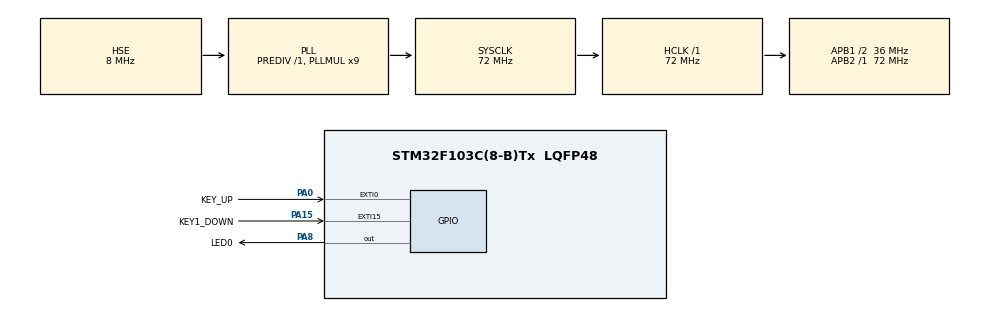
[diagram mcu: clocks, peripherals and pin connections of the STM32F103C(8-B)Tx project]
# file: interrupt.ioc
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Mcu.Family=STM32F1
Mcu.Name=STM32F103C(8-B)Tx
Mcu.Package=LQFP48
NVIC.EXTI0_IRQn=true\:2\:2\:true\:false\:true\:true\:true\:true
NVIC.EXTI15_10_IRQn=true\:2\:2\:true\:false\:true\:true\:true\:true
NVIC.PriorityGroup=NVIC_PRIORITYGROUP_2
PA0-WKUP.GPIO_Label=KEY_UP
PA0-WKUP.GPIO_PuPd=GPIO_PULLDOWN
PA0-WKUP.Signal=GPXTI0
PA13.Mode=Serial_Wire
PA13.Signal=SYS_JTMS-SWDIO
PA14.Mode=Serial_Wire
PA14.Signal=SYS_JTCK-SWCLK
PA15.GPIO_Label=KEY1_DOWN
PA15.GPIO_ModeDefaultEXTI=GPIO_MODE_IT_FALLING
PA15.GPIO_PuPd=GPIO_PULLUP
PA15.Signal=GPXTI15
PA8.GPIO_Label=LED0
PA8.Signal=GPIO_Output
PC14-OSC32_IN.Mode=LSE-External-Oscillator
PC14-OSC32_IN.Signal=RCC_OSC32_IN
PC15-OSC32_OUT.Mode=LSE-External-Oscillator
PC15-OSC32_OUT.Signal=RCC_OSC32_OUT
PD0-OSC_IN.Mode=HSE-External-Oscillator
PD0-OSC_IN.Signal=RCC_OSC_IN
PD1-OSC_OUT.Mode=HSE-External-Oscillator
PD1-OSC_OUT.Signal=RCC_OSC_OUT
ProjectManager.HeapSize=0x200
ProjectManager.StackSize=0x400
ProjectManager.TargetToolchain=Makefile
RCC.AHBFreq_Value=72000000
RCC.APB1CLKDivider=RCC_HCLK_DIV2
RCC.APB1Freq_Value=36000000
RCC.APB1TimFreq_Value=72000000
RCC.APB2Freq_Value=72000000
RCC.APB2TimFreq_Value=72000000
RCC.HCLKFreq_Value=72000000
RCC.PLLMUL=RCC_PLL_MUL9
RCC.PLLSourceVirtual=RCC_PLLSOURCE_HSE
RCC.SYSCLKFreq_VALUE=72000000
RCC.SYSCLKSource=RCC_SYSCLKSOURCE_PLLCLK
RCC.USBFreq_Value=72000000
board=custom

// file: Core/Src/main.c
/* USER CODE BEGIN Header */
/**
  ******************************************************************************
  * @file           : main.c
  * @brief          : Main program body
  ******************************************************************************
  * @attention
  *
  * Copyright (c) 2024 STMicroelectronics.
  * All rights reserved.
  *
  * This software is licensed under terms that can be found in the LICENSE file
  * in the root directory of this software component.
  * If no LICENSE file comes with this software, it is provided AS-IS.
  *
  ******************************************************************************
  */
/* USER CODE END Header */
#include "main.h"

/* USER CODE BEGIN Includes */
#include "delay.h"
#include "oled.h"
/* USER CODE END Includes */

void SystemClock_Config(void);
static void MX_GPIO_Init(void);

int main(void)
{

  /* MCU Configuration--------------------------------------------------------*/

  /* Reset of all peripherals, Initializes the Flash interface and the Systick. */
  HAL_Init();

  /* Configure the system clock */
  SystemClock_Config();

  /* USER CODE BEGIN SysInit */
    delay_init(72);
    OLED_Init();
  /* USER CODE END SysInit */

  /* Initialize all configured peripherals */
  MX_GPIO_Init();

  /* Infinite loop */
  /* USER CODE BEGIN WHILE */
//    OLED_Init();

    counter = 0;
    uint16_t t_counter = counter;
    /*在(16, 0)位置显示字符串"Hello World!"，字体大小为8*16点阵*/
    OLED_ShowString(1, 1, "Counter: ", OLED_8X16);

    OLED_Update();

  while (1)
  {
    /* USER CODE END WHILE */
    if (t_counter != counter) {
        t_counter = counter;
        OLED_ShowNum(65, 1, t_counter, 5, OLED_8X16);
        OLED_Update();
    }

  }
}

void SystemClock_Config(void)
{
  RCC_OscInitTypeDef RCC_OscInitStruct = {0};
  RCC_ClkInitTypeDef RCC_ClkInitStruct = {0};

  /** Initializes the RCC Oscillators according to the specified parameters
  * in the RCC_OscInitTypeDef structure.
  */
  RCC_OscInitStruct.OscillatorType = RCC_OSCILLATORTYPE_HSE;
  RCC_OscInitStruct.HSEState = RCC_HSE_ON;
  RCC_OscInitStruct.HSEPredivValue = RCC_HSE_PREDIV_DIV1;
  RCC_OscInitStruct.HSIState = RCC_HSI_ON;
  RCC_OscInitStruct.PLL.PLLState = RCC_PLL_ON;
  RCC_OscInitStruct.PLL.PLLSource = RCC_PLLSOURCE_HSE;
  RCC_OscInitStruct.PLL.PLLMUL = RCC_PLL_MUL9;
  if (HAL_RCC_OscConfig(&RCC_OscInitStruct) != HAL_OK)
  {
    Error_Handler();
  }

  /** Initializes the CPU, AHB and APB buses clocks
  */
  RCC_ClkInitStruct.ClockType = RCC_CLOCKTYPE_HCLK|RCC_CLOCKTYPE_SYSCLK
                              |RCC_CLOCKTYPE_PCLK1|RCC_CLOCKTYPE_PCLK2;
  RCC_ClkInitStruct.SYSCLKSource = RCC_SYSCLKSOURCE_PLLCLK;
  RCC_ClkInitStruct.AHBCLKDivider = RCC_SYSCLK_DIV1;
  RCC_ClkInitStruct.APB1CLKDivider = RCC_HCLK_DIV2;
  RCC_ClkInitStruct.APB2CLKDivider = RCC_HCLK_DIV1;

  if (HAL_RCC_ClockConfig(&RCC_ClkInitStruct, FLASH_LATENCY_2) != HAL_OK)
  {
    Error_Handler();
  }
}

static void MX_GPIO_Init(void)
{
  GPIO_InitTypeDef GPIO_InitStruct = {0};

  /* GPIO Ports Clock Enable */
  __HAL_RCC_GPIOC_CLK_ENABLE();
  __HAL_RCC_GPIOA_CLK_ENABLE();

  /*Configure GPIO pin Output Level */
  HAL_GPIO_WritePin(LED0_GPIO_Port, LED0_Pin, GPIO_PIN_RESET);

  /*Configure GPIO pin : KEY_UP_Pin */
  GPIO_InitStruct.Pin = KEY_UP_Pin;
  GPIO_InitStruct.Mode = GPIO_MODE_IT_RISING;
  GPIO_InitStruct.Pull = GPIO_PULLDOWN;
  HAL_GPIO_Init(KEY_UP_GPIO_Port, &GPIO_InitStruct);

  /*Configure GPIO pin : LED0_Pin */
  GPIO_InitStruct.Pin = LED0_Pin;
  GPIO_InitStruct.Mode = GPIO_MODE_OUTPUT_PP;
  GPIO_InitStruct.Pull = GPIO_NOPULL;
  GPIO_InitStruct.Speed = GPIO_SPEED_FREQ_LOW;
  HAL_GPIO_Init(LED0_GPIO_Port, &GPIO_InitStruct);

  /*Configure GPIO pin : KEY1_DOWN_Pin */
  GPIO_InitStruct.Pin = KEY1_DOWN_Pin;
  GPIO_InitStruct.Mode = GPIO_MODE_IT_FALLING;
  GPIO_InitStruct.Pull = GPIO_PULLUP;
  HAL_GPIO_Init(KEY1_DOWN_GPIO_Port, &GPIO_InitStruct);

  /* EXTI interrupt init*/
  HAL_NVIC_SetPriority(EXTI0_IRQn, 2, 2);
  HAL_NVIC_EnableIRQ(EXTI0_IRQn);

  HAL_NVIC_SetPriority(EXTI15_10_IRQn, 2, 2);
  HAL_NVIC_EnableIRQ(EXTI15_10_IRQn);

}

void Error_Handler(void)
{
  __disable_irq();
  while (1)
  {
  }
}
